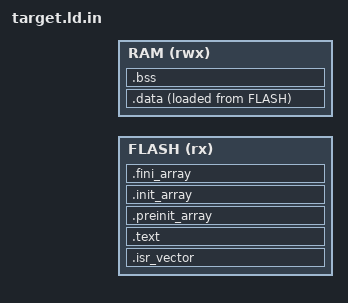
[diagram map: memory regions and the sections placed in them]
/* target.ld.in
 *
 * Copyright (C) 2026 wolfSSL Inc.
 *
 * This file is part of wolfBoot.
 *
 * wolfBoot is free software; you can redistribute it and/or modify
 * it under the terms of the GNU General Public License as published by
 * the Free Software Foundation; either version 3 of the License, or
 * (at your option) any later version.
 *
 * wolfBoot is distributed in the hope that it will be useful,
 * but WITHOUT ANY WARRANTY; without even the implied warranty of
 * MERCHANTABILITY or FITNESS FOR A PARTICULAR PURPOSE.  See the
 * GNU General Public License for more details.
 *
 * You should have received a copy of the GNU General Public License
 * along with this program; if not, write to the Free Software
 * Foundation, Inc., 51 Franklin Street, Fifth Floor, Boston, MA 02110-1335, USA
 */

/* Minimal linker script for the MCXW716C emulator test app.
 * @FLASH_ORIGIN@/@FLASH_SIZE@ are filled in by test.sh, @RAM_ORIGIN@ and
 * @RAM_SIZE@ by the Makefile (TZEN selects the non-secure SRAM window). */
MEMORY
{
    FLASH (rx)  : ORIGIN = @FLASH_ORIGIN@, LENGTH = @FLASH_SIZE@
    RAM   (rwx) : ORIGIN = @RAM_ORIGIN@,   LENGTH = @RAM_SIZE@
}

_estack = ORIGIN(RAM) + LENGTH(RAM);
_sidata = LOADADDR(.data);

SECTIONS
{
    .isr_vector :
    {
        KEEP(*(.isr_vector))
    } > FLASH

    .text :
    {
        *(.text*)
        *(.rodata*)
        *(.ARM.extab* .gnu.linkonce.armextab.*)
        *(.ARM.exidx* .gnu.linkonce.armexidx.*)
        *(.glue_7)
        *(.glue_7t)
        *(.eh_frame)
    } > FLASH

    .preinit_array :
    {
        __preinit_array_start = .;
        KEEP(*(.preinit_array*))
        __preinit_array_end = .;
    } > FLASH

    .init_array :
    {
        __init_array_start = .;
        KEEP(*(.init_array*))
        __init_array_end = .;
    } > FLASH

    .fini_array :
    {
        __fini_array_start = .;
        KEEP(*(.fini_array*))
        __fini_array_end = .;
    } > FLASH

    /* The FMU routines run from SRAM: the flash cannot be read mid-command */
    .data :
    {
        . = ALIGN(4);
        _sdata = .;
        KEEP(*(.ramcode*))
        . = ALIGN(4);
        *(.data*)
        . = ALIGN(4);
        _edata = .;
    } > RAM AT > FLASH

    .bss (NOLOAD) :
    {
        . = ALIGN(4);
        _sbss = .;
        *(.bss*)
        *(COMMON)
        . = ALIGN(4);
        _ebss = .;
    } > RAM
}
